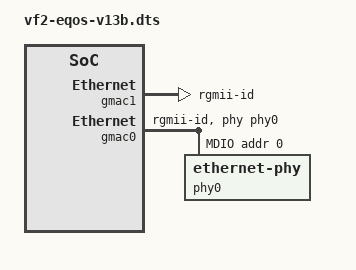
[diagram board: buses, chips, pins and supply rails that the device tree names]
/*
 * The first Ethernet port of a VisionFive 2 v1.3B (Linux v6.12
 * jh7110.dtsi, jh7110-common.dtsi and
 * jh7110-starfive-visionfive-2-v1.3b.dts): the transmit clock comes back
 * from the RGMII side, and the YT8531's delays, drive strengths and clock
 * inversions are the board's.
 */
/dts-v1/;
/include/ "vf2-eqos-soc.dtsi"

&soc {
	/* The second port, before the first so the glue must pass over it. */
	gmac1: ethernet@16040000 {
		compatible = "starfive,jh7110-dwmac", "snps,dwmac-5.20";
		reg = <0x0 0x16040000 0x0 0x10000>;
		phy-mode = "rgmii-id";
		status = "okay";
	};

	gmac0: ethernet@16030000 {
		compatible = "starfive,jh7110-dwmac", "snps,dwmac-5.20";
		reg = <0x0 0x16030000 0x0 0x10000>;
		clocks = <&aoncrg 3>, <&aoncrg 2>, <&syscrg 109>, <&aoncrg 6>, <&syscrg 111>;
		clock-names = "stmmaceth", "pclk", "ptp_ref", "tx", "gtx";
		resets = <&aoncrg 0>, <&aoncrg 1>;
		reset-names = "stmmaceth", "ahb";
		interrupts = <7>, <6>, <5>;
		interrupt-names = "macirq", "eth_wake_irq", "eth_lpi";
		rx-fifo-depth = <2048>;
		tx-fifo-depth = <2048>;
		snps,multicast-filter-bins = <64>;
		snps,perfect-filter-entries = <256>;
		snps,fixed-burst;
		snps,no-pbl-x8;
		snps,force_thresh_dma_mode;
		snps,axi-config = <&stmmac_axi_setup>;
		snps,tso;
		snps,en-tx-lpi-clockgating;
		snps,txpbl = <16>;
		snps,rxpbl = <16>;
		starfive,syscon = <&aon_syscon 0xc 0x12>;
		phy-handle = <&phy0>;
		phy-mode = "rgmii-id";
		local-mac-address = [6c cf 39 00 12 34];
		starfive,tx-use-rgmii-clk;
		assigned-clocks = <&aoncrg 5>;
		assigned-clock-parents = <&aoncrg 4>;
		status = "okay";

		mdio {
			#address-cells = <1>;
			#size-cells = <0>;
			compatible = "snps,dwmac-mdio";

			phy0: ethernet-phy@0 {
				reg = <0>;
				motorcomm,tx-clk-adj-enabled;
				motorcomm,tx-clk-100-inverted;
				motorcomm,tx-clk-1000-inverted;
				motorcomm,rx-clk-drv-microamp = <3970>;
				motorcomm,rx-data-drv-microamp = <2910>;
				rx-internal-delay-ps = <1500>;
				tx-internal-delay-ps = <1500>;
			};
		};
	};
};
